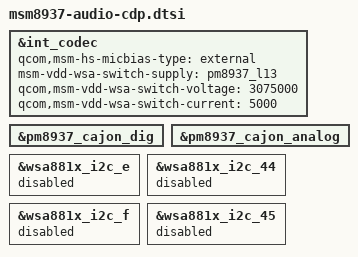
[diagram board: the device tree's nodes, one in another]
/*
 * Copyright (c) 2015-2016, The Linux Foundation. All rights reserved.
 *
 * This program is free software; you can redistribute it and/or modify
 * it under the terms of the GNU General Public License version 2 and
 * only version 2 as published by the Free Software Foundation.
 *
 * This program is distributed in the hope that it will be useful,
 * but WITHOUT ANY WARRANTY; without even the implied warranty of
 * MERCHANTABILITY or FITNESS FOR A PARTICULAR PURPOSE.  See the
 * GNU General Public License for more details.
 */

&int_codec {
	status = "okay";
	qcom,msm-hs-micbias-type = "external";

	msm-vdd-wsa-switch-supply = <&pm8937_l13>;
	qcom,msm-vdd-wsa-switch-voltage = <3075000>;
	qcom,msm-vdd-wsa-switch-current = <5000>;
};

&pm8937_cajon_dig {
	status = "okay";
};

&pm8937_cajon_analog {
	status = "okay";
};

&wsa881x_i2c_e {
	status = "disabled";
};

&wsa881x_i2c_44 {
	status = "disabled";
};

&wsa881x_i2c_f {
	status = "disabled";
};

&wsa881x_i2c_45 {
	status = "disabled";
};
